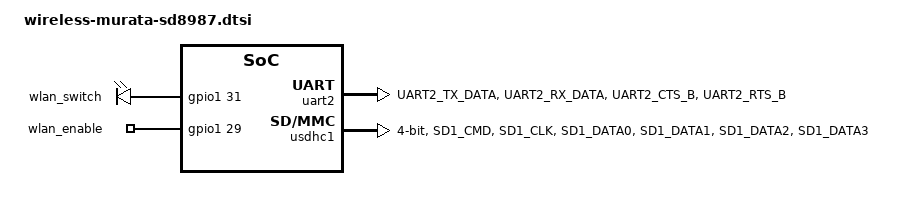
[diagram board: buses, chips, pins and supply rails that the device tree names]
/*
 * Copyright (C) 2020 CompeGPS Team S.L.
 * All rights reserved
 *
 */

/ {
	init-gpios-murata-sd8987 {
		compatible = "gpio-leds";
		pinctrl-names = "default";
		pinctrl-0 = <&pinctrl_wlan_ctrl>;

		wlan_switch {
			label = "wlan_switch";
			gpios = <&gpio1 31 GPIO_ACTIVE_HIGH>;
			default-state = "off";
		};
		wlan_enable {
			label = "wlan_enable";
			gpios = <&gpio1 29 GPIO_ACTIVE_HIGH>;
			default-state = "off";
		};
	};
};

/* Bluetooth UART */
&uart2 {
	pinctrl-names = "default";
	pinctrl-0 = <&pinctrl_uart2>;
	fsl,uart-has-rtscts;
	status = "okay";
};

&usdhc1 {
	pinctrl-names = "default", "state_100mhz", "state_200mhz";
	pinctrl-0 = <&pinctrl_usdhc1>;
	pinctrl-1 = <&pinctrl_usdhc1_100mhz>;
	pinctrl-2 = <&pinctrl_usdhc1_200mhz>;
	assigned-clock-rates = <0>, <50000000>;
	fsl,tuning-start-tap = <20>;
	bus-width = <4>;
	broken-cd;
	enable-sdio-wakeup;
	keep-power-in-suspend;
	status = "okay";
};

&iomuxc {
	imx6ul-evk {
		pinctrl_wlan_ctrl: wlanctrlgrp {
			fsl,pins = <
				MX6UL_PAD_UART4_RX_DATA__GPIO1_IO29		0x4001b0b0 /* WL_ENABLE */
				MX6UL_PAD_UART5_RX_DATA__GPIO1_IO31		0x1b0b0 /* WL_SWITCH */
			>;
		};

		pinctrl_uart2: uart2grp { /* Bluetooth */
			fsl,pins = <
				MX6UL_PAD_UART2_TX_DATA__UART2_DCE_TX	0x1b0b1
				MX6UL_PAD_UART2_RX_DATA__UART2_DCE_RX	0x1b0b1
				MX6UL_PAD_UART2_CTS_B__UART2_DCE_CTS	0x1b0b1
				MX6UL_PAD_UART2_RTS_B__UART2_DCE_RTS	0x1b0b1
			>;
		};

		pinctrl_usdhc1: usdhc1grp {
			fsl,pins = <
				MX6UL_PAD_SD1_CMD__USDHC1_CMD     0x17059
				MX6UL_PAD_SD1_CLK__USDHC1_CLK     0x10059
				MX6UL_PAD_SD1_DATA0__USDHC1_DATA0 0x17059
				MX6UL_PAD_SD1_DATA1__USDHC1_DATA1 0x17059
				MX6UL_PAD_SD1_DATA2__USDHC1_DATA2 0x17059
				MX6UL_PAD_SD1_DATA3__USDHC1_DATA3 0x17059
			>;
		};

		pinctrl_usdhc1_100mhz: usdhc1grp100mhz {
			fsl,pins = <
				MX6UL_PAD_SD1_CMD__USDHC1_CMD		0x170b9
				MX6UL_PAD_SD1_CLK__USDHC1_CLK		0x100b9
				MX6UL_PAD_SD1_DATA0__USDHC1_DATA0	0x170b9
				MX6UL_PAD_SD1_DATA1__USDHC1_DATA1	0x170b9
				MX6UL_PAD_SD1_DATA2__USDHC1_DATA2	0x170b9
				MX6UL_PAD_SD1_DATA3__USDHC1_DATA3	0x170b9
			>;
		};

		pinctrl_usdhc1_200mhz: usdhc1grp200mhz {
			fsl,pins = <
				MX6UL_PAD_SD1_CMD__USDHC1_CMD		0x170f9
				MX6UL_PAD_SD1_CLK__USDHC1_CLK		0x100f9
				MX6UL_PAD_SD1_DATA0__USDHC1_DATA0	0x170f9
				MX6UL_PAD_SD1_DATA1__USDHC1_DATA1	0x170f9
				MX6UL_PAD_SD1_DATA2__USDHC1_DATA2	0x170f9
				MX6UL_PAD_SD1_DATA3__USDHC1_DATA3	0x170f9
			>;
		};
	};
};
